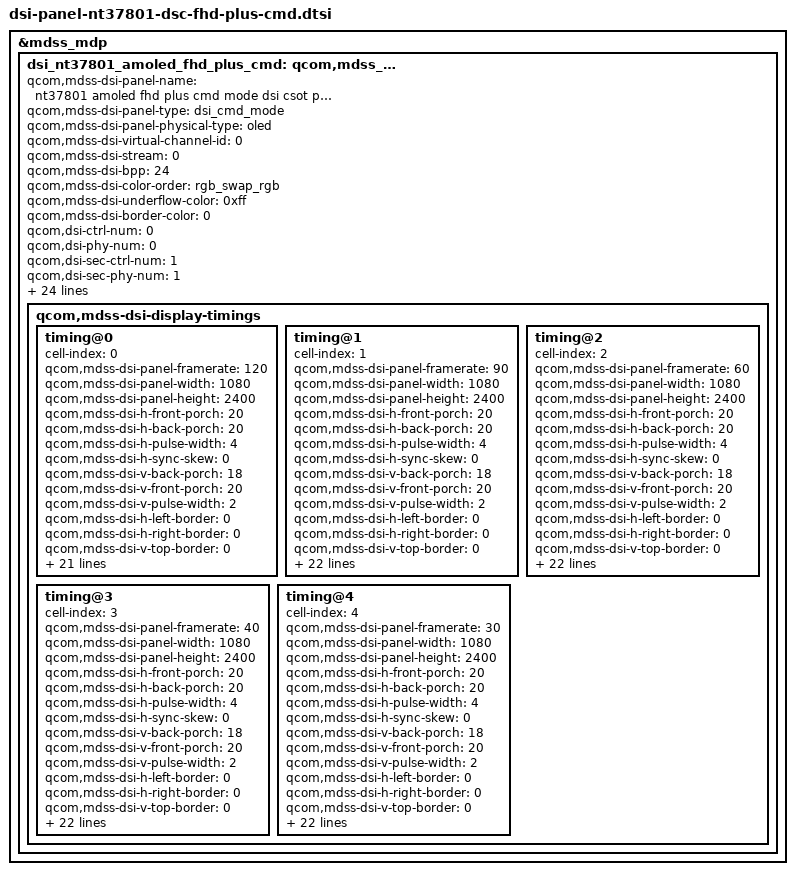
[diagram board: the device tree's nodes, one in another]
// SPDX-License-Identifier: BSD-3-Clause
/*
 * Copyright (c) 2024 Qualcomm Innovation Center, Inc. All rights reserved.
 */

&mdss_mdp {
	dsi_nt37801_amoled_fhd_plus_cmd: qcom,mdss_dsi_nt37801_fhd_plus_cmd {
		qcom,mdss-dsi-panel-name =
			"nt37801 amoled fhd plus cmd mode dsi csot panel with DSC";
		qcom,mdss-dsi-panel-type = "dsi_cmd_mode";
		qcom,mdss-dsi-panel-physical-type = "oled";
		qcom,mdss-dsi-virtual-channel-id = <0>;
		qcom,mdss-dsi-stream = <0>;
		qcom,mdss-dsi-bpp = <24>;
		qcom,mdss-dsi-color-order = "rgb_swap_rgb";
		qcom,mdss-dsi-underflow-color = <0xff>;
		qcom,mdss-dsi-border-color = <0>;

		qcom,dsi-ctrl-num = <0>;
		qcom,dsi-phy-num = <0>;
		qcom,dsi-sec-ctrl-num = <1>;
		qcom,dsi-sec-phy-num = <1>;

		qcom,mdss-dsi-traffic-mode = "non_burst_sync_event";
		qcom,mdss-dsi-lane-map = "lane_map_0123";
		qcom,mdss-dsi-bllp-eof-power-mode;
		qcom,mdss-dsi-bllp-power-mode;
		qcom,mdss-dsi-lane-0-state;
		qcom,mdss-dsi-lane-1-state;
		qcom,mdss-dsi-lane-2-state;
		qcom,mdss-dsi-lane-3-state;
		qcom,mdss-dsi-dma-trigger = "trigger_sw";
		qcom,mdss-dsi-mdp-trigger = "none";
		qcom,mdss-dsi-reset-sequence = <1 10>, <0 10>, <1 10>;

		qcom,mdss-dsi-te-pin-select = <1>;
		qcom,mdss-dsi-wr-mem-start = <0x2c>;
		qcom,mdss-dsi-wr-mem-continue = <0x3c>;
		qcom,mdss-dsi-te-dcs-command = <1>;
		qcom,mdss-dsi-te-check-enable;
		qcom,mdss-dsi-te-using-te-pin;
		qcom,spr-pack-type = "pentile";
		qcom,mdss-dsi-panel-hdr-enabled;
		qcom,mdss-dsi-panel-hdr-color-primaries = <15150 15750 34250
			15700 12250 35800 6750 2550>;
		qcom,mdss-dsi-panel-peak-brightness = <13000000>;
		qcom,mdss-dsi-panel-blackness-level = <10>;
		qcom,mdss-dsi-display-timings {
			timing@0 {
				cell-index = <0>;
				qcom,mdss-dsi-panel-framerate = <120>;
				qcom,mdss-dsi-panel-width = <1080>;
				qcom,mdss-dsi-panel-height = <2400>;
				qcom,mdss-dsi-h-front-porch = <20>;
				qcom,mdss-dsi-h-back-porch = <20>;
				qcom,mdss-dsi-h-pulse-width = <4>;
				qcom,mdss-dsi-h-sync-skew = <0>;
				qcom,mdss-dsi-v-back-porch = <18>;
				qcom,mdss-dsi-v-front-porch = <20>;
				qcom,mdss-dsi-v-pulse-width = <2>;
				qcom,mdss-dsi-h-left-border = <0>;
				qcom,mdss-dsi-h-right-border = <0>;
				qcom,mdss-dsi-v-top-border = <0>;
				qcom,mdss-dsi-v-bottom-border = <0>;
				qcom,mdss-dsi-panel-jitter = <0x4 0x1>;

				qcom,mdss-dsi-timing-switch-command = [
					39 01 00 00 00 00 05 2A 00 00 04 37
					39 01 00 00 00 00 05 2B 00 00 09 5F
					39 01 00 00 00 00 02 8F 01
					39 01 00 00 00 00 02 2f 00
					39 01 00 00 00 00 02 26 00
					39 01 00 00 00 00 06 f0 55 aa 52 08 00
					39 01 00 00 00 00 06 c0 54 c0 00 21 43
					39 01 00 00 00 00 06 f0 55 aa 52 08 02
					39 01 00 00 00 00 02 cc 30
					39 01 00 00 00 00 02 ce 01
					39 01 00 00 20 00 02 cc 00
				];

				qcom,mdss-dsi-on-command = [
					39 01 00 00 00 00 06 F0 55 AA 52 08 01
					39 01 00 00 00 00 02 6F 01
					39 01 00 00 00 00 04 C5 0B 0B 0B
					39 01 00 00 00 00 05 FF AA 55 A5 80
					39 01 00 00 00 00 02 6F 02
					39 01 00 00 00 00 02 F5 10
					39 01 00 00 00 00 02 6F 1B
					39 01 00 00 00 00 02 F4 55
					39 01 00 00 00 00 02 6F 18
					39 01 00 00 00 00 02 F8 19
					39 01 00 00 00 00 02 6F 0F
					39 01 00 00 00 00 02 FC 00
					39 01 00 00 00 00 05 2A 00 00 04 37
					39 01 00 00 00 00 05 2B 00 00 09 5F
					39 01 00 00 00 00 02 90 03
					39 01 00 00 00 00 13 91 89 28 00 28 c2
					   00 02 0e 03 dd 00 07 02 77 02 8B 10
					   f0
					39 01 00 00 00 00 05 ff aa 55 a5 81
					39 01 00 00 00 00 02 6f 23
					39 01 00 00 00 00 15 fb 00 01 00 11 33
					   33 33 55 57 d0 00 00 44 56 77 78 9a
					   bc dd f0
					39 01 00 00 00 00 13 93 89 28 00 28 D2 00 02 25 03 B6 00 07 02 AB 02 8B 10 F0
					39 01 00 00 00 00 13 95 89 28 00 28 D2 00 01 C3 02 FC 00 05 02 AB 03 D1 10 F0
					39 01 00 00 00 00 02 03 00
					39 01 00 00 00 00 02 8F 01
					39 01 00 00 00 00 02 6F 06
					39 01 00 00 00 00 02 F3 DC
					39 01 00 00 00 00 02 26 00
					39 01 00 00 00 00 02 35 00
					39 01 00 00 00 00 05 3B 00 18 00 10
					39 01 00 00 00 00 02 53 20
					39 01 00 00 00 00 07 51 07 FF 07 FF 0F FF
					39 01 00 00 00 00 02 5A 01
					39 01 00 00 00 00 02 5F 00
					39 01 00 00 00 00 02 9C 01
					05 01 00 00 00 00 01 2C
					39 01 00 00 00 00 02 2F 00

					05 01 00 00 78 00 01 11
					05 01 00 00 14 00 01 29
				];

				qcom,mdss-dsi-off-command = [
					05 01 00 00 14 00 02 28 00
					05 01 00 00 78 00 02 10 00];
				qcom,mdss-dsi-on-command-state = "dsi_lp_mode";
				qcom,mdss-dsi-off-command-state = "dsi_hs_mode";
				qcom,mdss-dsi-timing-switch-command-state =
					"dsi_lp_mode";
				qcom,mdss-dsi-h-sync-pulse = <0>;
				qcom,compression-mode = "dsc";
				qcom,mdss-dsc-rc-override_v1;
				qcom,mdss-dsc-slice-height = <40>;
				qcom,mdss-dsc-slice-width = <540>;
				qcom,mdss-dsc-slice-per-pkt = <1>;
				qcom,mdss-dsc-bit-per-component = <8>;
				qcom,mdss-dsc-bit-per-pixel = <8>;
				qcom,mdss-dsc-block-prediction-enable;
			};

			timing@1 {
				cell-index = <1>;
				qcom,mdss-dsi-panel-framerate = <90>;
				qcom,mdss-dsi-panel-width = <1080>;
				qcom,mdss-dsi-panel-height = <2400>;
				qcom,mdss-dsi-h-front-porch = <20>;
				qcom,mdss-dsi-h-back-porch = <20>;
				qcom,mdss-dsi-h-pulse-width = <4>;
				qcom,mdss-dsi-h-sync-skew = <0>;
				qcom,mdss-dsi-v-back-porch = <18>;
				qcom,mdss-dsi-v-front-porch = <20>;
				qcom,mdss-dsi-v-pulse-width = <2>;
				qcom,mdss-dsi-h-left-border = <0>;
				qcom,mdss-dsi-h-right-border = <0>;
				qcom,mdss-dsi-v-top-border = <0>;
				qcom,mdss-dsi-v-bottom-border = <0>;
				qcom,mdss-dsi-panel-jitter = <0x4 0x1>;
				qcom,mdss-dsi-panel-clockrate = <680000000>;

				qcom,mdss-dsi-timing-switch-command = [
					39 01 00 00 00 00 05 2a 00 00 04 37
					39 01 00 00 00 00 05 2b 00 00 09 5f
					39 01 00 00 00 00 02 8f 01
					39 01 00 00 00 00 02 2f 01
					39 01 00 00 00 00 02 26 01
					39 01 00 00 00 00 06 f0 55 aa 52 08 00
					39 01 00 00 00 00 06 c0 54 c0 00 24 45
					39 01 00 00 00 00 06 f0 55 aa 52 08 02
					39 01 00 00 00 00 02 cc 30
					39 01 00 00 00 00 02 ce 01
					39 01 00 00 20 00 02 cc 00
				];

				qcom,mdss-dsi-on-command = [
					39 01 00 00 00 00 06 F0 55 AA 52 08 01
					39 01 00 00 00 00 02 6F 01
					39 01 00 00 00 00 04 C5 0B 0B 0B
					39 01 00 00 00 00 05 FF AA 55 A5 80
					39 01 00 00 00 00 02 6F 06
					39 01 00 00 00 00 02 F3 DC
					39 01 00 00 00 00 02 6F 02
					39 01 00 00 00 00 02 F5 10
					39 01 00 00 00 00 02 6F 1B
					39 01 00 00 00 00 02 F4 55
					39 01 00 00 00 00 02 6F 18
					39 01 00 00 00 00 02 F8 19
					39 01 00 00 00 00 02 6F 0F
					39 01 00 00 00 00 02 FC 00
					39 01 00 00 00 00 05 2a 00 00 04 37
					39 01 00 00 00 00 05 2b 00 00 09 5f
					39 01 00 00 00 00 02 90 03
					39 01 00 00 00 00 13 91 89 28 00 28 c2
					   00 02 0e 03 dd 00 07 02 77 02 8B 10
					   f0
					39 01 00 00 00 00 05 ff aa 55 a5 81
					39 01 00 00 00 00 02 6f 23
					39 01 00 00 00 00 15 fb 00 01 00 11 33
					   33 33 55 57 d0 00 00 44 56 77 78 9a
					   bc dd f0
					39 01 00 00 00 00 02 35 00
					39 01 00 00 00 00 05 3B 00 18 00 10
					39 01 00 00 00 00 02 53 20
					39 01 00 00 00 00 07 51 07 FF 07 FF 0F
					   FF
					39 01 00 00 00 00 02 5A 01
					39 01 00 00 00 00 02 5F 00
					39 01 00 00 00 00 02 9C 01
					05 01 00 00 00 00 01 2C
					39 01 00 00 00 00 02 8f 01
					39 01 00 00 00 00 02 2f 01
					39 01 00 00 00 00 02 26 01
					39 01 00 00 00 00 06 f0 55 aa 52 08 00
					39 01 00 00 00 00 06 c0 54 c0 00 24 45
					39 01 00 00 00 00 06 f0 55 aa 52 08 02
					39 01 00 00 00 00 02 cc 30
					39 01 00 00 00 00 02 ce 01
					39 01 00 00 20 00 02 cc 00
					39 01 00 00 00 00 06 F0 55 AA 52 08 01
					39 01 00 00 00 00 05 B2 55 01 FF 03
					05 01 00 00 78 00 01 11
					05 01 00 00 14 00 01 29
				];

				qcom,mdss-dsi-off-command = [
					05 01 00 00 14 00 02 28 00
					05 01 00 00 78 00 02 10 00];
				qcom,mdss-dsi-on-command-state = "dsi_lp_mode";
				qcom,mdss-dsi-off-command-state = "dsi_hs_mode";
				qcom,mdss-dsi-timing-switch-command-state =
					"dsi_lp_mode";
				qcom,mdss-dsi-h-sync-pulse = <0>;
				qcom,compression-mode = "dsc";
				qcom,mdss-dsc-rc-override_v1;
				qcom,mdss-dsc-slice-height = <40>;
				qcom,mdss-dsc-slice-width = <540>;
				qcom,mdss-dsc-slice-per-pkt = <1>;
				qcom,mdss-dsc-bit-per-component = <8>;
				qcom,mdss-dsc-bit-per-pixel = <8>;
				qcom,mdss-dsc-block-prediction-enable;
			};

			timing@2 {
				cell-index = <2>;
				qcom,mdss-dsi-panel-framerate = <60>;
				qcom,mdss-dsi-panel-width = <1080>;
				qcom,mdss-dsi-panel-height = <2400>;
				qcom,mdss-dsi-h-front-porch = <20>;
				qcom,mdss-dsi-h-back-porch = <20>;
				qcom,mdss-dsi-h-pulse-width = <4>;
				qcom,mdss-dsi-h-sync-skew = <0>;
				qcom,mdss-dsi-v-back-porch = <18>;
				qcom,mdss-dsi-v-front-porch = <20>;
				qcom,mdss-dsi-v-pulse-width = <2>;
				qcom,mdss-dsi-h-left-border = <0>;
				qcom,mdss-dsi-h-right-border = <0>;
				qcom,mdss-dsi-v-top-border = <0>;
				qcom,mdss-dsi-v-bottom-border = <0>;
				qcom,mdss-dsi-panel-jitter = <0x4 0x1>;
				qcom,mdss-dsi-panel-clockrate = <680000000>;

				qcom,mdss-dsi-timing-switch-command = [
					39 01 00 00 00 00 05 2a 00 00 04 37
					39 01 00 00 00 00 05 2b 00 00 09 5f
					39 01 00 00 00 00 02 8f 01
					39 01 00 00 00 00 02 2f 00
					39 01 00 00 00 00 02 26 01
					39 01 00 00 00 00 02 5a 01
					39 01 00 00 00 00 02 2f 30
					39 01 00 00 00 00 06 f0 55 aa 52 08 00
					39 01 00 00 00 00 02 6f 1c
					39 01 00 00 00 00 09 ba 91 01 01 00 01
					   01 01 00
					39 01 00 00 00 00 06 f0 55 aa 52 08 00
					39 01 00 00 00 00 06 c0 54 c0 00 21 43
					39 01 00 00 00 00 06 f0 55 aa 52 08 02
					39 01 00 00 00 00 02 cc 30
					39 01 00 00 00 00 02 ce 01
					39 01 00 00 20 00 02 cc 00
				];

				qcom,mdss-dsi-on-command = [
					39 01 00 00 00 00 06 F0 55 AA 52 08 01
					39 01 00 00 00 00 02 6F 01
					39 01 00 00 00 00 04 C5 0B 0B 0B
					39 01 00 00 00 00 05 FF AA 55 A5 80
					39 01 00 00 00 00 02 6F 02
					39 01 00 00 00 00 02 F5 10
					39 01 00 00 00 00 02 6F 1B
					39 01 00 00 00 00 02 F4 55
					39 01 00 00 00 00 02 6F 18
					39 01 00 00 00 00 02 F8 19
					39 01 00 00 00 00 02 6F 0F
					39 01 00 00 00 00 02 FC 00
					39 01 00 00 00 00 05 2a 00 00 04 37
					39 01 00 00 00 00 05 2b 00 00 09 5f
					39 01 00 00 00 00 02 90 03
					39 01 00 00 00 00 13 91 89 28 00 28 c2
					   00 02 0e 03 dd 00 07 02 77 02 8B 10
					   f0
					39 01 00 00 00 00 05 ff aa 55 a5 81
					39 01 00 00 00 00 02 6f 23
					39 01 00 00 00 00 15 fb 00 01 00 11 33
					   33 33 55 57 d0 00 00 44 56 77 78 9a
					   bc dd f0
					39 01 00 00 00 00 02 6F 06
					39 01 00 00 00 00 02 F3 DC
					39 01 00 00 00 00 02 26 00
					39 01 00 00 00 00 02 35 00
					39 01 00 00 00 00 05 3B 00 18 00 10
					39 01 00 00 00 00 02 53 20
					39 01 00 00 00 00 07 51 07 FF 07 FF 0F
					   FF
					39 01 00 00 00 00 02 5A 01
					39 01 00 00 00 00 02 5F 00
					39 01 00 00 00 00 02 9C 01
					05 01 00 00 00 00 01 2C
					39 01 00 00 00 00 02 8f 01
					39 01 00 00 00 00 02 2f 00
					39 01 00 00 00 00 02 26 01
					39 01 00 00 00 00 02 5a 01
					39 01 00 00 00 00 02 2f 30
					39 01 00 00 00 00 06 f0 55 aa 52 08 00
					39 01 00 00 00 00 02 6f 1c
					39 01 00 00 00 00 09 ba 91 01 01 00 01
					   01 01 00
					39 01 00 00 00 00 06 f0 55 aa 52 08 00
					39 01 00 00 00 00 06 c0 54 c0 00 21 43
					39 01 00 00 00 00 06 f0 55 aa 52 08 02
					39 01 00 00 00 00 02 cc 30
					39 01 00 00 00 00 02 ce 01
					39 01 00 00 20 00 02 cc 00
					39 01 00 00 00 00 06 F0 55 AA 52 08 01
					39 01 00 00 00 00 05 B2 55 01 FF 03
					05 01 00 00 78 00 01 11
					05 01 00 00 14 00 01 29
				];

				qcom,mdss-dsi-off-command = [
					05 01 00 00 14 00 02 28 00
					05 01 00 00 78 00 02 10 00];
				qcom,mdss-dsi-on-command-state = "dsi_lp_mode";
				qcom,mdss-dsi-off-command-state = "dsi_hs_mode";
				qcom,mdss-dsi-timing-switch-command-state =
					"dsi_lp_mode";
				qcom,mdss-dsi-h-sync-pulse = <0>;
				qcom,compression-mode = "dsc";
				qcom,mdss-dsc-rc-override_v1;
				qcom,mdss-dsc-slice-height = <40>;
				qcom,mdss-dsc-slice-width = <540>;
				qcom,mdss-dsc-slice-per-pkt = <1>;
				qcom,mdss-dsc-bit-per-component = <8>;
				qcom,mdss-dsc-bit-per-pixel = <8>;
				qcom,mdss-dsc-block-prediction-enable;
			};

			timing@3 {
				cell-index = <3>;
				qcom,mdss-dsi-panel-framerate = <40>;
				qcom,mdss-dsi-panel-width = <1080>;
				qcom,mdss-dsi-panel-height = <2400>;
				qcom,mdss-dsi-h-front-porch = <20>;
				qcom,mdss-dsi-h-back-porch = <20>;
				qcom,mdss-dsi-h-pulse-width = <4>;
				qcom,mdss-dsi-h-sync-skew = <0>;
				qcom,mdss-dsi-v-back-porch = <18>;
				qcom,mdss-dsi-v-front-porch = <20>;
				qcom,mdss-dsi-v-pulse-width = <2>;
				qcom,mdss-dsi-h-left-border = <0>;
				qcom,mdss-dsi-h-right-border = <0>;
				qcom,mdss-dsi-v-top-border = <0>;
				qcom,mdss-dsi-v-bottom-border = <0>;
				qcom,mdss-dsi-panel-jitter = <0x4 0x1>;
				qcom,mdss-dsi-panel-clockrate = <680000000>;

				qcom,mdss-dsi-timing-switch-command = [
					39 01 00 00 00 00 05 2a 00 00 04 37
					39 01 00 00 00 00 05 2b 00 00 09 5f
					39 01 00 00 00 00 02 8f 01
					39 01 00 00 00 00 02 2f 00
					39 01 00 00 00 00 02 26 01
					39 01 00 00 00 00 02 5a 01
					39 01 00 00 00 00 02 2f 30
					39 01 00 00 00 00 06 f0 55 aa 52 08 00
					39 01 00 00 00 00 02 6f 1c
					39 01 00 00 00 00 09 ba 91 02 02 00 01
					   02 02 00
					39 01 00 00 00 00 06 f0 55 aa 52 08 00
					39 01 00 00 00 00 06 c0 54 c0 00 21 43
					39 01 00 00 00 00 06 f0 55 aa 52 08 02
					39 01 00 00 00 00 02 cc 30
					39 01 00 00 00 00 02 ce 01
					39 01 00 00 20 00 02 cc 00
				];

				qcom,mdss-dsi-on-command = [
					39 01 00 00 00 00 06 F0 55 AA 52 08 01
					39 01 00 00 00 00 02 6F 01
					39 01 00 00 00 00 04 C5 0B 0B 0B
					39 01 00 00 00 00 05 FF AA 55 A5 80
					39 01 00 00 00 00 02 6F 02
					39 01 00 00 00 00 02 F5 10
					39 01 00 00 00 00 02 6F 1B
					39 01 00 00 00 00 02 F4 55
					39 01 00 00 00 00 02 6F 18
					39 01 00 00 00 00 02 F8 19
					39 01 00 00 00 00 02 6F 0F
					39 01 00 00 00 00 02 FC 00
					39 01 00 00 00 00 05 2a 00 00 04 37
					39 01 00 00 00 00 05 2b 00 00 09 5f
					39 01 00 00 00 00 02 90 03
					39 01 00 00 00 00 13 91 89 28 00 28 c2
					   00 02 0e 03 dd 00 07 02 77 02 8B 10
					   f0
					39 01 00 00 00 00 05 ff aa 55 a5 81
					39 01 00 00 00 00 02 6f 23
					39 01 00 00 00 00 15 fb 00 01 00 11 33
					   33 33 55 57 d0 00 00 44 56 77 78 9a
					   bc dd f0
					39 01 00 00 00 00 02 6F 06
					39 01 00 00 00 00 02 F3 DC
					39 01 00 00 00 00 02 26 00
					39 01 00 00 00 00 02 35 00
					39 01 00 00 00 00 05 3B 00 18 00 10
					39 01 00 00 00 00 02 53 20
					39 01 00 00 00 00 07 51 07 FF 07 FF 0F
					   FF
					39 01 00 00 00 00 02 5A 01
					39 01 00 00 00 00 02 5F 00
					39 01 00 00 00 00 02 9C 01
					05 01 00 00 00 00 01 2C
					39 01 00 00 00 00 02 8f 01
					39 01 00 00 00 00 02 2f 00
					39 01 00 00 00 00 02 26 01
					39 01 00 00 00 00 02 5a 01
					39 01 00 00 00 00 02 2f 30
					39 01 00 00 00 00 06 f0 55 aa 52 08 00
					39 01 00 00 00 00 02 6f 1c
					39 01 00 00 00 00 09 ba 91 02 02 00 01
					   02 02 00
					39 01 00 00 00 00 06 f0 55 aa 52 08 00
					39 01 00 00 00 00 06 c0 54 c0 00 21 43
					39 01 00 00 00 00 06 f0 55 aa 52 08 02
					39 01 00 00 00 00 02 cc 30
					39 01 00 00 00 00 02 ce 01
					39 01 00 00 20 00 02 cc 00
					39 01 00 00 00 00 06 F0 55 AA 52 08 01
					39 01 00 00 00 00 05 B2 55 01 FF 03
					05 01 00 00 78 00 01 11
					05 01 00 00 14 00 01 29
				];

				qcom,mdss-dsi-off-command = [
					05 01 00 00 14 00 02 28 00
					05 01 00 00 78 00 02 10 00];
				qcom,mdss-dsi-on-command-state = "dsi_lp_mode";
				qcom,mdss-dsi-off-command-state = "dsi_hs_mode";
				qcom,mdss-dsi-timing-switch-command-state =
					"dsi_lp_mode";
				qcom,mdss-dsi-h-sync-pulse = <0>;
				qcom,compression-mode = "dsc";
				qcom,mdss-dsc-rc-override_v1;
				qcom,mdss-dsc-slice-height = <40>;
				qcom,mdss-dsc-slice-width = <540>;
				qcom,mdss-dsc-slice-per-pkt = <1>;
				qcom,mdss-dsc-bit-per-component = <8>;
				qcom,mdss-dsc-bit-per-pixel = <8>;
				qcom,mdss-dsc-block-prediction-enable;
			};

			timing@4 {
				cell-index = <4>;
				qcom,mdss-dsi-panel-framerate = <30>;
				qcom,mdss-dsi-panel-width = <1080>;
				qcom,mdss-dsi-panel-height = <2400>;
				qcom,mdss-dsi-h-front-porch = <20>;
				qcom,mdss-dsi-h-back-porch = <20>;
				qcom,mdss-dsi-h-pulse-width = <4>;
				qcom,mdss-dsi-h-sync-skew = <0>;
				qcom,mdss-dsi-v-back-porch = <18>;
				qcom,mdss-dsi-v-front-porch = <20>;
				qcom,mdss-dsi-v-pulse-width = <2>;
				qcom,mdss-dsi-h-left-border = <0>;
				qcom,mdss-dsi-h-right-border = <0>;
				qcom,mdss-dsi-v-top-border = <0>;
				qcom,mdss-dsi-v-bottom-border = <0>;
				qcom,mdss-dsi-panel-jitter = <0x4 0x1>;
				qcom,mdss-dsi-panel-clockrate = <680000000>;

				qcom,mdss-dsi-timing-switch-command = [
					39 01 00 00 00 00 05 2a 00 00 04 37
					39 01 00 00 00 00 05 2b 00 00 09 5f
					39 01 00 00 00 00 02 8f 01
					39 01 00 00 00 00 02 2f 00
					39 01 00 00 00 00 02 26 01
					39 01 00 00 00 00 02 5a 01
					39 01 00 00 00 00 02 2f 30
					39 01 00 00 00 00 06 f0 55 aa 52 08 00
					39 01 00 00 00 00 02 6f 1c
					39 01 00 00 00 00 09 ba 91 03 03 00 01
					   03 03 00
					39 01 00 00 00 00 06 f0 55 aa 52 08 00
					39 01 00 00 00 00 06 c0 54 c0 00 21 43
					39 01 00 00 00 00 06 f0 55 aa 52 08 02
					39 01 00 00 00 00 02 cc 30
					39 01 00 00 00 00 02 ce 01
					39 01 00 00 20 00 02 cc 00
				];

				qcom,mdss-dsi-on-command = [
					39 01 00 00 00 00 06 F0 55 AA 52 08 01
					39 01 00 00 00 00 02 6F 01
					39 01 00 00 00 00 04 C5 0B 0B 0B
					39 01 00 00 00 00 05 FF AA 55 A5 80
					39 01 00 00 00 00 02 6F 02
					39 01 00 00 00 00 02 F5 10
					39 01 00 00 00 00 02 6F 1B
					39 01 00 00 00 00 02 F4 55
					39 01 00 00 00 00 02 6F 18
					39 01 00 00 00 00 02 F8 19
					39 01 00 00 00 00 02 6F 0F
					39 01 00 00 00 00 02 FC 00
					39 01 00 00 00 00 05 2a 00 00 04 37
					39 01 00 00 00 00 05 2b 00 00 09 5f
					39 01 00 00 00 00 02 90 03
					39 01 00 00 00 00 13 91 89 28 00 28 c2
					   00 02 0e 03 dd 00 07 02 77 02 8B 10
					   f0
					39 01 00 00 00 00 05 ff aa 55 a5 81
					39 01 00 00 00 00 02 6f 23
					39 01 00 00 00 00 15 fb 00 01 00 11 33
					   33 33 55 57 d0 00 00 44 56 77 78 9a
					   bc dd f0
					39 01 00 00 00 00 02 6F 06
					39 01 00 00 00 00 02 F3 DC
					39 01 00 00 00 00 02 26 00
					39 01 00 00 00 00 02 35 00
					39 01 00 00 00 00 05 3B 00 18 00 10
					39 01 00 00 00 00 02 53 20
					39 01 00 00 00 00 07 51 07 FF 07 FF 0F
					   FF
					39 01 00 00 00 00 02 5A 01
					39 01 00 00 00 00 02 5F 00
					39 01 00 00 00 00 02 9C 01
					05 01 00 00 00 00 01 2C
					39 01 00 00 00 00 02 8f 01
					39 01 00 00 00 00 02 2f 00
					39 01 00 00 00 00 02 26 01
					39 01 00 00 00 00 02 5a 01
					39 01 00 00 00 00 02 2f 30
					39 01 00 00 00 00 06 f0 55 aa 52 08 00
					39 01 00 00 00 00 02 6f 1c
					39 01 00 00 00 00 09 ba 91 03 03 00 01
					   03 03 00
					39 01 00 00 00 00 06 f0 55 aa 52 08 00
					39 01 00 00 00 00 06 c0 54 c0 00 21 43
					39 01 00 00 00 00 06 f0 55 aa 52 08 02
					39 01 00 00 00 00 02 cc 30
					39 01 00 00 00 00 02 ce 01
					39 01 00 00 20 00 02 cc 00
					39 01 00 00 00 00 06 F0 55 AA 52 08 01
					39 01 00 00 00 00 05 B2 55 01 FF 03
					05 01 00 00 78 00 01 11
					05 01 00 00 14 00 01 29
				];

				qcom,mdss-dsi-off-command = [
					05 01 00 00 14 00 02 28 00
					05 01 00 00 78 00 02 10 00];
				qcom,mdss-dsi-on-command-state = "dsi_lp_mode";
				qcom,mdss-dsi-off-command-state = "dsi_hs_mode";
				qcom,mdss-dsi-timing-switch-command-state =
					"dsi_lp_mode";
				qcom,mdss-dsi-h-sync-pulse = <0>;
				qcom,compression-mode = "dsc";
				qcom,mdss-dsc-rc-override_v1;
				qcom,mdss-dsc-slice-height = <40>;
				qcom,mdss-dsc-slice-width = <540>;
				qcom,mdss-dsc-slice-per-pkt = <1>;
				qcom,mdss-dsc-bit-per-component = <8>;
				qcom,mdss-dsc-bit-per-pixel = <8>;
				qcom,mdss-dsc-block-prediction-enable;
			};
		};
	};
};
